# target register map
Vendor: Vango; Series: TARGET; File version: 1.0
CPU: CM0 r0p0, little endian, no MPU, no FPU, 2 interrupt priority bits
Registers are 32-bit, read-write, reset 0x0 unless marked. A register's access mark holds for its fields unless they carry their own. Offsets are from the block's base; [hi:lo] are bit positions; {n}, {i} and the like mark numbered series.

## PMU — Power Management Unit.
Base 0x40014000
0x00 DSLEEPEN — PMU deep sleep enable register.
  [31] WKU ro — Current wake-up signal status.
0x04 DSLEEPPASS — PMU deep sleep password register.
  [0] UNLOCK ro — This bit indicates the entry of deep-sleep mode has been unlocked and is ready to entry deep-sleep mode.
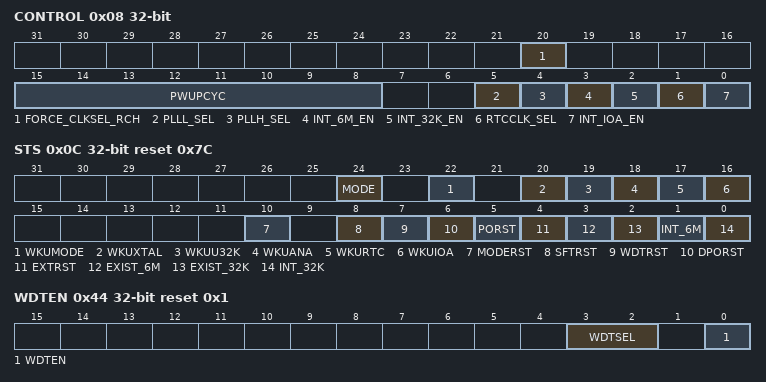
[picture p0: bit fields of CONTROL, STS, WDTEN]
0x08 CONTROL — PMU control register.
  [20] FORCE_CLKSEL_RCH — Wake up clock selection for idle mode.
  [15:8] PWUPCYC — Power-up cycle count.
  [5] PLLL_SEL — Low speed PLL input clock selection.
  [4] PLLH_SEL — High speed PLL input clock selection.
  [3] INT_6M_EN — 6.5536M XTAL absent interrupt enable register.
  [2] INT_32K_EN — 32K XTAL absent interrupt enable register.
  [1] RTCCLK_SEL — RTC Clock selection.
  [0] INT_IOA_EN — IOA0~15 interrupt enable register.
0x0C STS reset 0x7C — PMU Status register.
  [24] MODE ro — This register shows the current status of MODE pin.
  [22] WKUMODE ro — This register is used to indicate if the previous wake-up source from deep-sleep mode is from MODE pin change from 1 to 0.
  [20] WKUXTAL ro — This register is used to indicate if the previous wake-up source from deep-sleep mode is from crystal absent detection module.
  [19] WKUU32K ro — This register is used to indicate if the previous wake-up source from deep-sleep mode is from UART 32K module.
  [18] WKUANA ro — This register is used to indicate if the previous wake-up source from deep-sleep mode is from Analog module.
  [17] WKURTC ro — This register is used to indicate if the previous wake-up source from deep-sleep mode is from RTC module.
  [16] WKUIOA ro — This register is used to indicate if the previous wake-up source from deep-sleep mode is from IOA wake-up.
  [10] MODERST write-1-clears — This register indicates that a MODE wakeup reset from sleep or deep sleep mode has happened.
  [8] SFTRST write-1-clears — This register indicates that a soft reset has happened.
  [7] WDTRST write-1-clears — This bit indicated if the last reset is caused by WDT.
  [6] DPORST write-1-clears — This bit indicated if the last reset is cause by internal digital power-on reset signal.
  [5] PORST write-1-clears — This bit indicated if the last reset is cause by internal power-on reset signal.
  [4] EXTRST write-1-clears — This bit indicated if the last interrupt is cause by external reset signal.
  [3] EXIST_6M ro — 6.5536M XTAL exist status register.
  [2] EXIST_32K ro — 32K XTAL exist status register.
  [1] INT_6M write-1-clears — This bit represents the 6.5536M crystal absent interrupt status.
  [0] INT_32K write-1-clears — This bit represents the 32K crystal absent interrupt status.
0x40 WDTPASS — Watch dog timing unlock register.
  [0] UNLOCK ro — This bit indicates the watch dog timer enable register has been unlocked and is ready to change the watch dog enable control register.
0x44 WDTEN reset 0x1 — Watch dog timer enable register.
  [3:2] WDTSEL — This register is used to control the WDT counting period.
    0=2_Second; 1=4_Second; 2=8_Second; 3=16_Second
  [0] WDTEN — This bit indicates the watch dog timer is enable.
0x48 WDTCLR — Watch dog timer clear register.
  [15:0] WDTCNT — This register shows the current counter value of wat dog timer.
{0x400+4i} RAM[{i}] (i=0..63) — PMU 32 bits Retention RAM x.
  [31:0] RAM — There is a 256 bytes (64x32) SRAM embedded in the PMU controller. This RAM can keep data during deep-sleep mode. Only word access is allowed to these ports.

## PWM0 — Timers are 16 bits timers with PWM and capture function.
Base 0x40012900
Same registers: PWM1 0x40012920, PWM2 0x40012940, PWM3 0x40012960
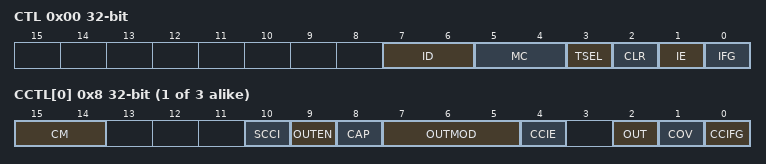
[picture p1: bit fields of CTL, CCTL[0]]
0x00 CTL — Control register of PWM Timer 0
  [7:6] ID — Input clock divider control for PWM timer x.
    0=Div2; 1=Div4; 2=Div8; 3=Div16
  [5:4] MC — PWM Timer mode control.
    0=Timer_stop; 1=Up_count_mode; 2=Continuous_mode; 3=UpDown_mode
  [3] TSEL — Clock source selection.
  [2] CLR — TAR clear register
  [1] IE — Interrupt enable register of PWM timer x.
  [0] IFG write-1-clears — Interrupt status flag of PWM timer.
0x04 TAR ro reset not defined — Current count register of PWM Timer x.
  [15:0] TAR
{0x8+4i} CCTL[{i}] (i=0..2) — Compare/capture control register x(x=0~3) for PWM timer x.
  [15:14] CM — Capture edge selection.
    0=Disable; 1=Rising; 2=Falling; 3=Both
  [10] SCCI ro — The read only register shows the INx input value when the TAR is equal to CCRx.
  [9] OUTEN — OUTx output enable control register.
  [8] CAP — Capture/Compare mode selection.
  [7:5] OUTMOD — Output mode selection.
    0=Constant_mode; 1=Set_mode; 2=Toggle_Reset_mode; 3=Set_Reset_mode; 4=Toggle_mode; 5=Reset_mode; 6=Toggle_Set_mode; 7=Reset_Set_mode
  [4] CCIE — Capture/Compare interrupt enable register.
  [2] OUT — This bit is used to control the output value of OUTx when OUTMOD is set to 0.
  [1] COV write-1-clears — Capture overflow flag.
  [0] CCIFG write-1-clears — Under capture mode, this bit will be set when a capture event is coming and the TAR will be latched into CCRx. Under compare mode, this bit will be set when TAR=CCRx.
{0x14+4i} CCR[{i}] (i=0..2) — Compare/capture data register x for PWM timer x.
  [15:0] CCRx — Compare/Capture data register.
